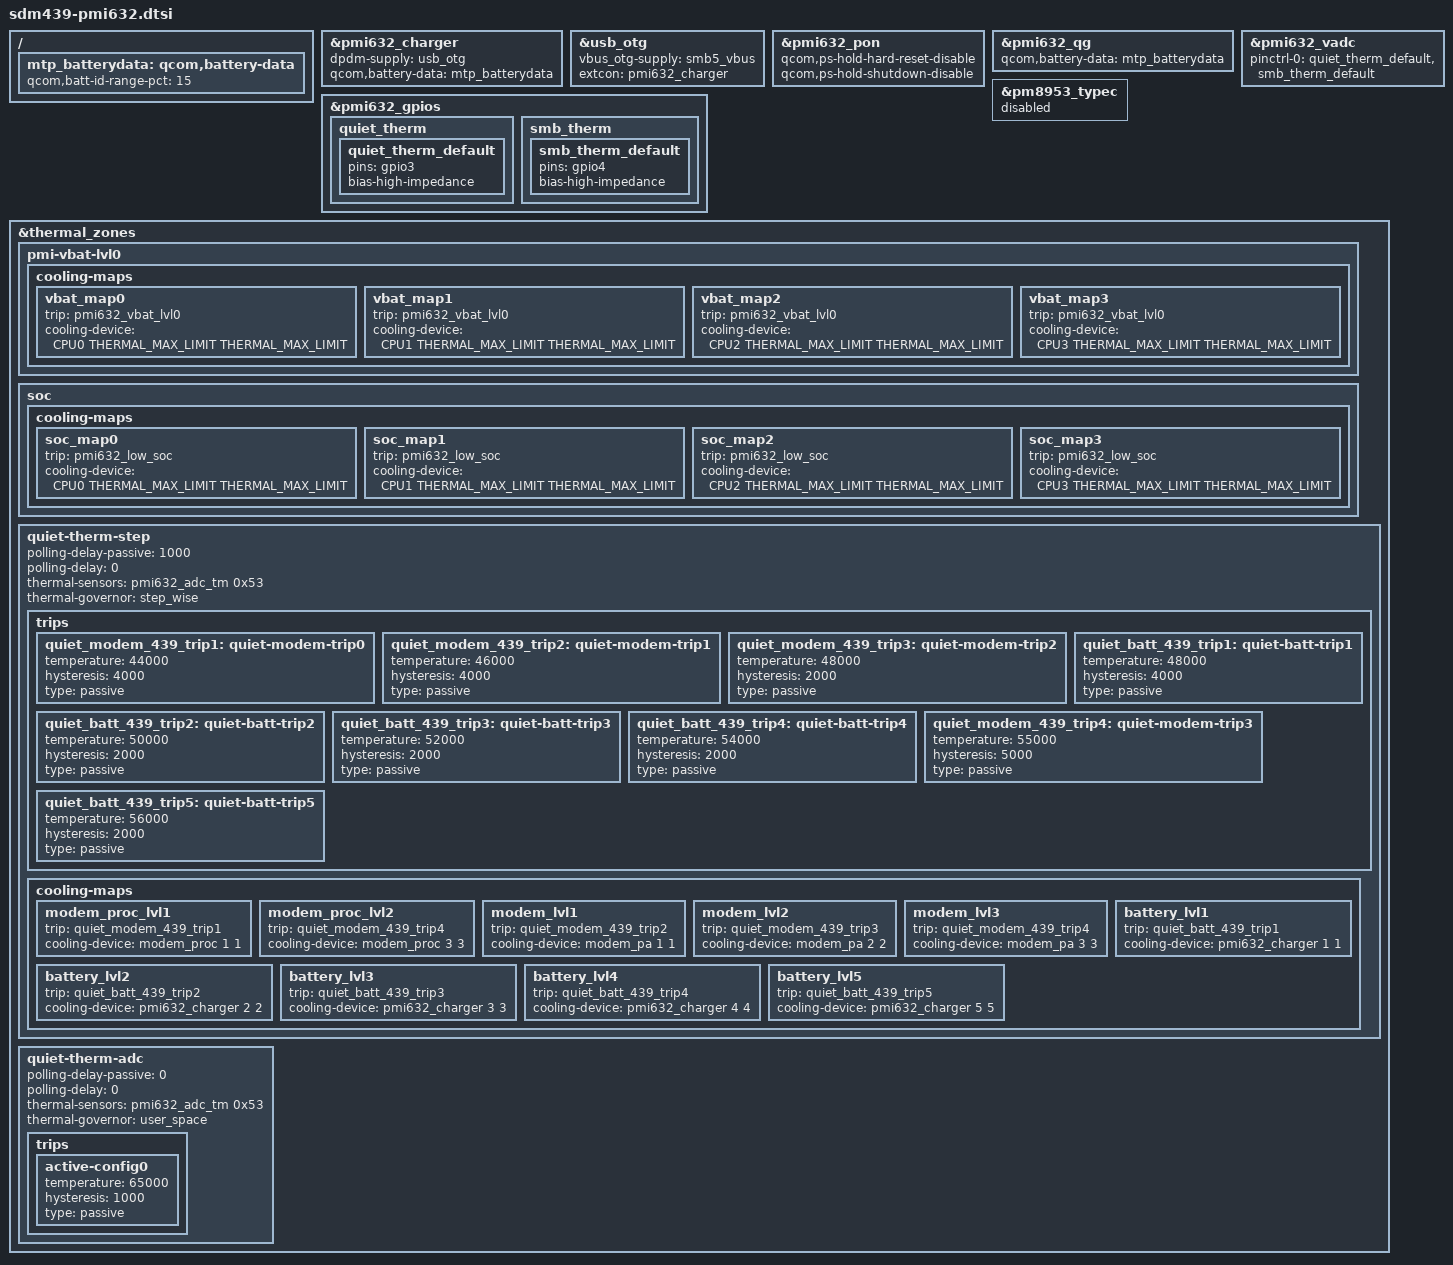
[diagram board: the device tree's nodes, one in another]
/*
 * Copyright (c) 2018, The Linux Foundation. All rights reserved.
 *
 * This program is free software; you can redistribute it and/or modify
 * it under the terms of the GNU General Public License version 2 and
 * only version 2 as published by the Free Software Foundation.
 *
 * This program is distributed in the hope that it will be useful,
 * but WITHOUT ANY WARRANTY; without even the implied warranty of
 * MERCHANTABILITY or FITNESS FOR A PARTICULAR PURPOSE.  See the
 * GNU General Public License for more details.
 */

#include "pmi632.dtsi"

&pmi632_charger {
	dpdm-supply = <&usb_otg>;
};

&usb_otg {
	vbus_otg-supply = <&smb5_vbus>;
	extcon = <&pmi632_charger>;
};

&pmi632_pon {
	qcom,ps-hold-hard-reset-disable;
	qcom,ps-hold-shutdown-disable;
};

/{
	mtp_batterydata: qcom,battery-data {
		qcom,batt-id-range-pct = <15>;
		#include "qg-batterydata-ascent-3450mah.dtsi"
		#include "qg-batterydata-mlp356477-2800mah.dtsi"
	};
};

&pmi632_qg {
	qcom,battery-data = <&mtp_batterydata>;
};

&pmi632_charger {
	qcom,battery-data = <&mtp_batterydata>;
};

&pmi632_vadc {
	pinctrl-names = "default";
	pinctrl-0 = <&quiet_therm_default &smb_therm_default>;
};

&pmi632_gpios {
	quiet_therm {
		quiet_therm_default: quiet_therm_default {
			pins = "gpio3";
			bias-high-impedance;
		};
	};

	smb_therm {
		smb_therm_default: smb_therm_default {
			pins = "gpio4";
			bias-high-impedance;
		};
	};
};

&pm8953_typec {
	status = "disabled";
};

&thermal_zones {
	pmi-vbat-lvl0 {
		cooling-maps {
			vbat_map0 {
				trip = <&pmi632_vbat_lvl0>;
				cooling-device =
					<&CPU0 THERMAL_MAX_LIMIT
						THERMAL_MAX_LIMIT>;
			};
			vbat_map1 {
				trip = <&pmi632_vbat_lvl0>;
				cooling-device =
					<&CPU1 THERMAL_MAX_LIMIT
						THERMAL_MAX_LIMIT>;
			};
			vbat_map2 {
				trip = <&pmi632_vbat_lvl0>;
				cooling-device =
					<&CPU2 THERMAL_MAX_LIMIT
						THERMAL_MAX_LIMIT>;
			};
			vbat_map3 {
				trip = <&pmi632_vbat_lvl0>;
				cooling-device =
					<&CPU3 THERMAL_MAX_LIMIT
						THERMAL_MAX_LIMIT>;
			};
		};
	};

	soc {
		cooling-maps {
			soc_map0 {
				trip = <&pmi632_low_soc>;
				cooling-device =
					<&CPU0 THERMAL_MAX_LIMIT
						THERMAL_MAX_LIMIT>;
			};
			soc_map1 {
				trip = <&pmi632_low_soc>;
				cooling-device =
					<&CPU1 THERMAL_MAX_LIMIT
						THERMAL_MAX_LIMIT>;
			};
			soc_map2 {
				trip = <&pmi632_low_soc>;
				cooling-device =
					<&CPU2 THERMAL_MAX_LIMIT
						THERMAL_MAX_LIMIT>;
			};
			soc_map3 {
				trip = <&pmi632_low_soc>;
				cooling-device =
					<&CPU3 THERMAL_MAX_LIMIT
						THERMAL_MAX_LIMIT>;
			};
		};
	};

	quiet-therm-step {
		polling-delay-passive = <1000>;
		polling-delay = <0>;
		thermal-sensors = <&pmi632_adc_tm 0x53>;
		thermal-governor = "step_wise";

		trips {
			quiet_modem_439_trip1: quiet-modem-trip0 {
				temperature = <44000>;
				hysteresis = <4000>;
				type = "passive";
			};
			quiet_modem_439_trip2: quiet-modem-trip1 {
				temperature = <46000>;
				hysteresis = <4000>;
				type = "passive";
			};
			quiet_modem_439_trip3: quiet-modem-trip2 {
				temperature = <48000>;
				hysteresis = <2000>;
				type = "passive";
			};
			quiet_batt_439_trip1: quiet-batt-trip1 {
				temperature = <48000>;
				hysteresis = <4000>;
				type = "passive";
			};
			quiet_batt_439_trip2: quiet-batt-trip2 {
				temperature = <50000>;
				hysteresis = <2000>;
				type = "passive";
			};
			quiet_batt_439_trip3: quiet-batt-trip3 {
				temperature = <52000>;
				hysteresis = <2000>;
				type = "passive";
			};
			quiet_batt_439_trip4: quiet-batt-trip4 {
				temperature = <54000>;
				hysteresis = <2000>;
				type = "passive";
			};
			quiet_modem_439_trip4: quiet-modem-trip3 {
				temperature = <55000>;
				hysteresis = <5000>;
				type = "passive";
			};
			quiet_batt_439_trip5: quiet-batt-trip5 {
				temperature = <56000>;
				hysteresis = <2000>;
				type = "passive";
			};
		};

		cooling-maps {
			modem_proc_lvl1 {
				trip = <&quiet_modem_439_trip1>;
				cooling-device = <&modem_proc 1 1>;
			};
			modem_proc_lvl2 {
				trip = <&quiet_modem_439_trip4>;
				cooling-device = <&modem_proc 3 3>;
			};
			modem_lvl1 {
				trip = <&quiet_modem_439_trip2>;
				cooling-device = <&modem_pa 1 1>;
			};
			modem_lvl2 {
				trip = <&quiet_modem_439_trip3>;
				cooling-device = <&modem_pa 2 2>;
			};
			modem_lvl3 {
				trip = <&quiet_modem_439_trip4>;
				cooling-device = <&modem_pa 3 3>;
			};
			battery_lvl1 {
				trip = <&quiet_batt_439_trip1>;
				cooling-device = <&pmi632_charger 1 1>;
			};
			battery_lvl2 {
				trip = <&quiet_batt_439_trip2>;
				cooling-device = <&pmi632_charger 2 2>;
			};
			battery_lvl3 {
				trip = <&quiet_batt_439_trip3>;
				cooling-device = <&pmi632_charger 3 3>;
			};
			battery_lvl4 {
				trip = <&quiet_batt_439_trip4>;
				cooling-device = <&pmi632_charger 4 4>;
			};
			battery_lvl5 {
				trip = <&quiet_batt_439_trip5>;
				cooling-device = <&pmi632_charger 5 5>;
			};
		};
	};

	quiet-therm-adc {
		polling-delay-passive = <0>;
		polling-delay = <0>;
		thermal-sensors = <&pmi632_adc_tm 0x53>;
		thermal-governor = "user_space";

		trips {
			active-config0 {
				temperature = <65000>;
				hysteresis = <1000>;
				type = "passive";
			};
		};
	};
};
